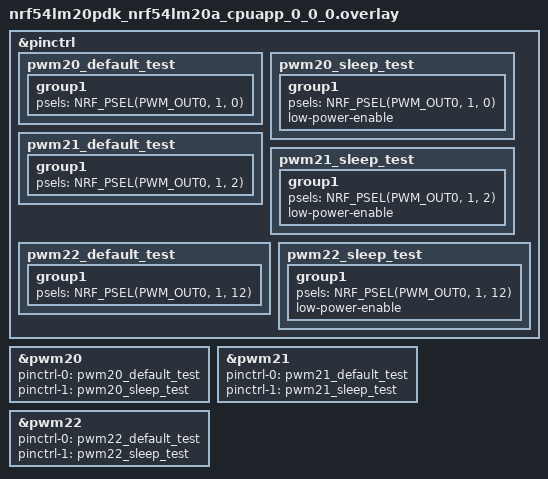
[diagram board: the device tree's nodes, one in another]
/*
 * Copyright (c) 2025 Nordic Semiconductor ASA
 *
 * SPDX-License-Identifier: LicenseRef-Nordic-5-Clause
 */

&pinctrl {
	pwm20_default_test: pwm20_default_test {
		group1 {
			psels = <NRF_PSEL(PWM_OUT0, 1, 0)>;
		};
	};

	pwm20_sleep_test: pwm20_sleep_test {
		group1 {
			psels = <NRF_PSEL(PWM_OUT0, 1, 0)>;
			low-power-enable;
		};
	};

	pwm21_default_test: pwm21_default_test {
		group1 {
			psels = <NRF_PSEL(PWM_OUT0, 1, 2)>;
		};
	};

	pwm21_sleep_test: pwm21_sleep_test {
		group1 {
			psels = <NRF_PSEL(PWM_OUT0, 1, 2)>;
			low-power-enable;
		};
	};

	pwm22_default_test: pwm22_default_test {
		group1 {
			psels = <NRF_PSEL(PWM_OUT0, 1, 12)>;
		};
	};

	pwm22_sleep_test: pwm22_sleep_test {
		group1 {
			psels = <NRF_PSEL(PWM_OUT0, 1, 12)>;
			low-power-enable;
		};
	};
};

&pwm20 {
	status = "okay";
	pinctrl-0 = <&pwm20_default_test>;
	pinctrl-1 = <&pwm20_sleep_test>;
	pinctrl-names = "default", "sleep";
};

&pwm21 {
	status = "okay";
	pinctrl-0 = <&pwm21_default_test>;
	pinctrl-1 = <&pwm21_sleep_test>;
	pinctrl-names = "default", "sleep";
};

&pwm22 {
	status = "okay";
	pinctrl-0 = <&pwm22_default_test>;
	pinctrl-1 = <&pwm22_sleep_test>;
	pinctrl-names = "default", "sleep";
};
